LIN_description_file;
LIN_protocol_version = "2.0";
LIN_language_version = "2.0";
LIN_speed = 19.2 kbps;

Nodes {
  Master: bcm, 5.0 ms, 0.1 ms ;
  Slaves: scs, wbp, wpa,

Signals {
    Left_Turn_Btn: 1, 0, lsn, bcm ;
    Right_Turn_Btn: 1, 0, lsn, bcm ;
    Hazard_Btn: 1, 0, lsn, bcm ;
    Low_Beam_Btn: 1, 0, lsn, bcm ;
    High_Beam_Btn: 1, 0, lsn, bcm ;
    Brake_Btn: 1, 0, lsn, bcm ;
    Reverse_Btn: 1, 0, lsn, bcm ;
    Fog_Btn: 1, 0, lsn, bcm ;
    Flash_Btn: 1, 0, lsn, bcm ;
}

Frames {
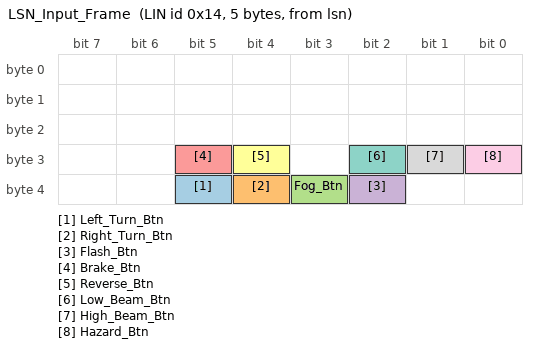
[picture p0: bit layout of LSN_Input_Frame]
    LSN_Input_Frame : 0x14, lsn, 5 {
        Left_Turn_Btn, 37 ;
        Right_Turn_Btn, 36 ;
        Fog_Btn, 35 ;
        Flash_Btn, 34 ;
        Brake_Btn, 29 ;
        Reverse_Btn, 28 ;
        Low_Beam_Btn, 26 ;
        High_Beam_Btn, 25 ;
        Hazard_Btn, 24 ;
    }
}

Schedule_tables {
    Normal_Table {
        LSN_Input_Frame delay 5.0 ms ;
    }
    Diagnostic_Table {
        MasterReq delay 10.0 ms ;
        SlaveResp delay 10.0 ms ;
    }
}
y 10.0 ms ;
        SlaveResp delay 10.0 ms ;
    }
}
